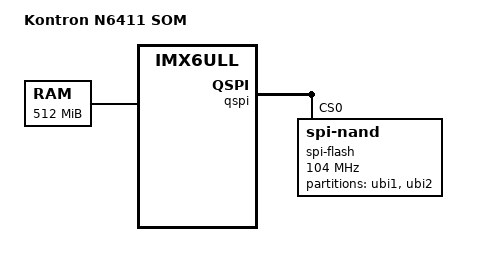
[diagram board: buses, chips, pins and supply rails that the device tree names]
// SPDX-License-Identifier: GPL-2.0
/*
 * Copyright (C) 2017 exceet electronics GmbH
 * Copyright (C) 2018 Kontron Electronics GmbH
 */

#include "imx6ull.dtsi"
#include "imx6ul-kontron-n6x1x-som-common.dtsi"

/ {
	model = "Kontron N6411 SOM";
	compatible = "kontron,imx6ull-n6311-som", "fsl,imx6ull";

	memory@80000000 {
		reg = <0x80000000 0x20000000>;
		device_type = "memory";
	};
};

&qspi {
	spi-flash@0 {
		#address-cells = <1>;
		#size-cells = <1>;
		compatible = "spi-nand";
		spi-max-frequency = <104000000>;
		spi-tx-bus-width = <4>;
		spi-rx-bus-width = <4>;
		reg = <0>;

		partition@0 {
			label = "ubi1";
			reg = <0x00000000 0x08000000>;
		};

		partition@8000000 {
			label = "ubi2";
			reg = <0x08000000 0x18000000>;
		};
	};
};
